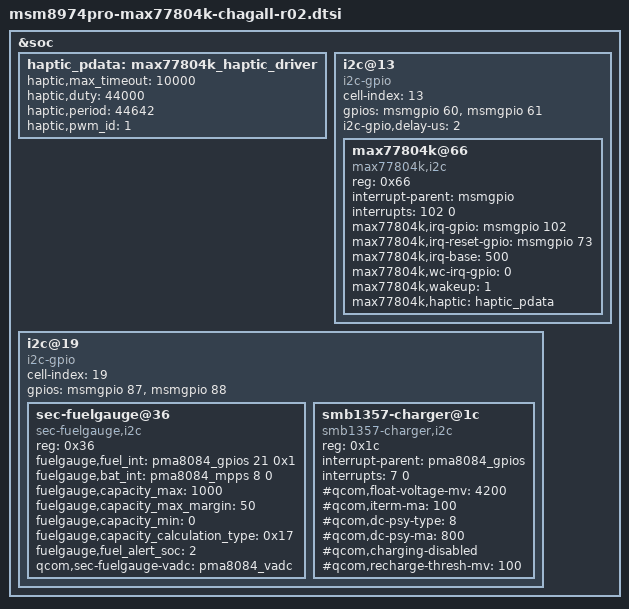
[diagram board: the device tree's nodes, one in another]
/* Copyright (c) 2012, The Linux Foundation. All rights reserved.
 *
 * This program is free software; you can redistribute it and/or modify
 * it under the terms of the GNU General Public License version 2 and
 * only version 2 as published by the Free Software Foundation.
 *
 * This program is distributed in the hope that it will be useful,
 * but WITHOUT ANY WARRANTY; without even the implied warranty of
 * MERCHANTABILITY or FITNESS FOR A PARTICULAR PURPOSE.  See the
 * GNU General Public License for more details.
 */

&soc {

	haptic_pdata: max77804k_haptic_driver {
		haptic,max_timeout = <10000>;
		haptic,duty = <44000>;
		haptic,period = <44642>;
		haptic,pwm_id = <1>;
	};
	i2c@13 {
		cell-index = <13>;
		compatible = "i2c-gpio";
		gpios = <&msmgpio 60 0 /* sda */
			 &msmgpio 61 0 /* scl */
			 >;
		i2c-gpio,delay-us = <2>;
		#address-cells = <1>;
		#size-cells = <0>;

		max77804k@66 {
			compatible = "max77804k,i2c";
			reg = <0x66>;
			interrupt-parent = <&msmgpio>;
			interrupts = <102 0>;
			max77804k,irq-gpio = <&msmgpio 102 0x00>;
			max77804k,irq-reset-gpio = <&msmgpio 73 0x00>;
			max77804k,irq-base = <500>;
			max77804k,wc-irq-gpio = <0>;
			max77804k,wakeup = <1>;
			max77804k,haptic = <&haptic_pdata>;
		};
	};
	i2c@19 {
		cell-index = <19>;
		compatible = "i2c-gpio";
		gpios = <&msmgpio 87 0 /* sda */
		&msmgpio 88 0 /* scl */
		>;
		#address-cells = <1>;
		#size-cells = <0>;
		sec-fuelgauge@36 {
			compatible = "sec-fuelgauge,i2c";
			reg = <0x36>;
			fuelgauge,fuel_int = <&pma8084_gpios 21 0x1>;
			fuelgauge,bat_int = <&pma8084_mpps 8 0>;

			fuelgauge,capacity_max = <1000>;
			fuelgauge,capacity_max_margin = <50>;
			fuelgauge,capacity_min = <0>;
			fuelgauge,capacity_calculation_type = <0x17>;
			fuelgauge,fuel_alert_soc = <2>;
			/* fuelgaguge,repeated_fuelalert; */
			qcom,sec-fuelgauge-vadc = <&pma8084_vadc>;
		};

		smb1357-charger@1c {
			compatible = "smb1357-charger,i2c";
			reg = <0x1c>;
			interrupt-parent = <&pma8084_gpios>;
			interrupts = <7 0>;
			#qcom,float-voltage-mv = <4200>;
			#qcom,iterm-ma = <100>;
			#qcom,dc-psy-type = <8>;
			#qcom,dc-psy-ma = <800>;
			#qcom,charging-disabled;
			#qcom,recharge-thresh-mv = <100>;
		};
	};
};
